# HC32K118 register map
File version: 1.0
CPU: CM0+ r0p1, little endian, no MPU, no FPU, 2 interrupt priority bits
Registers are 32-bit, read-write, reset 0x0 unless marked. A register's access mark holds for its fields unless they carry their own. Offsets are from the block's base; [hi:lo] are bit positions; {n}, {i} and the like mark numbered series.

## PERIC
Base 0x40013400
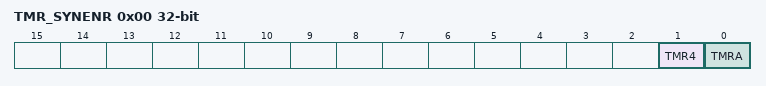
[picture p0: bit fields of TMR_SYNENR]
0x00 TMR_SYNENR
  [1] TMR4, [0] TMRA

## PWC
Base 0x40014000
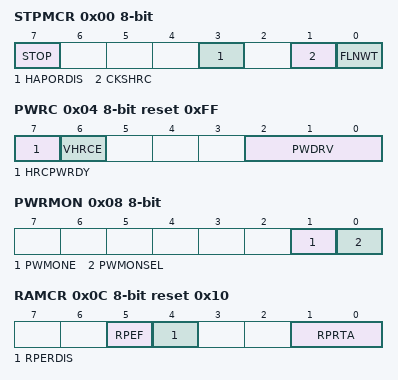
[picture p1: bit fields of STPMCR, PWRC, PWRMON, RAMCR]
0x00 STPMCR 8-bit
  [7] STOP, [3] HAPORDIS, [1] CKSHRC, [0] FLNWT
0x04 PWRC 8-bit reset 0xFF
  [7] HRCPWRDY, [6] VHRCE, [2:0] PWDRV
0x08 PWRMON 8-bit
  [1] PWMONE, [0] PWMONSEL
0x0C RAMCR 8-bit reset 0x10
  [5] RPEF, [4] RPERDIS, [1:0] RPRTA
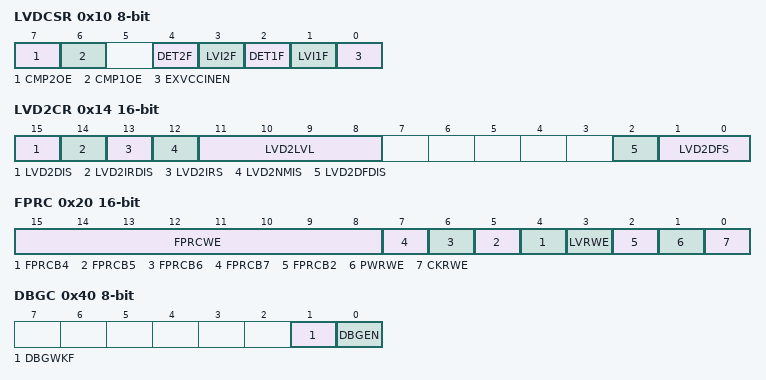
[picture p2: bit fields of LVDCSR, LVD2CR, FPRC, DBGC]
0x10 LVDCSR 8-bit
  [7] CMP2OE, [6] CMP1OE, [4] DET2F, [3] LVI2F, [2] DET1F, [1] LVI1F, [0] EXVCCINEN
0x14 LVD2CR 16-bit
  [15] LVD2DIS, [14] LVD2IRDIS, [13] LVD2IRS, [12] LVD2NMIS, [11:8] LVD2LVL, [2] LVD2DFDIS, [1:0] LVD2DFS
0x20 FPRC 16-bit
  [15:8] FPRCWE wo, [n] FPRCB{n} (n=4..7), [3] LVRWE, [2] FPRCB2, [1] PWRWE, [0] CKRWE
0x40 DBGC 8-bit
  [1] DBGWKF ro, [0] DBGEN

## RMU
Base 0x40014100
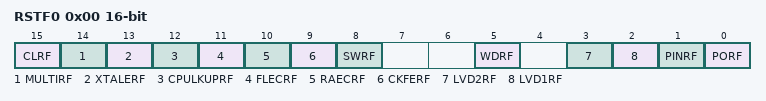
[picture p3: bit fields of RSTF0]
0x00 RSTF0 16-bit
  [15] CLRF, [14] MULTIRF, [13] XTALERF, [12] CPULKUPRF, [11] FLECRF, [10] RAECRF, [9] CKFERF, [8] SWRF, [5] WDRF, [3] LVD2RF, [2] LVD1RF, [1] PINRF, [0] PORF

## RTC
Base 0x4000D400
0x00 CR0 8-bit
  [0] RESET
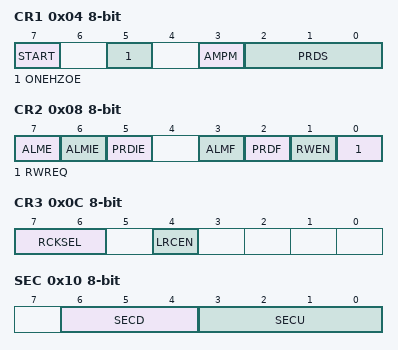
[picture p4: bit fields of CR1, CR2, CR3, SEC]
0x04 CR1 8-bit
  [7] START, [5] ONEHZOE, [3] AMPM, [2:0] PRDS
0x08 CR2 8-bit
  [7] ALME, [6] ALMIE, [5] PRDIE, [3] ALMF, [2] PRDF, [1] RWEN, [0] RWREQ
0x0C CR3 8-bit
  [7:6] RCKSEL, [4] LRCEN
0x10 SEC 8-bit
  [6:4] SECD, [3:0] SECU
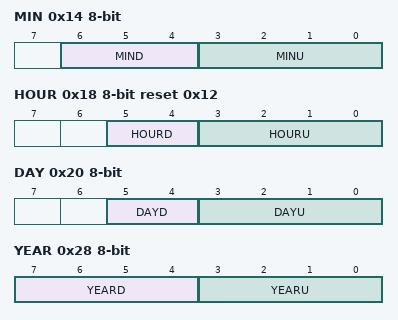
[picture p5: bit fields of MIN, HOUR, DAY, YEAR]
0x14 MIN 8-bit
  [6:4] MIND, [3:0] MINU
0x18 HOUR 8-bit reset 0x12
  [5:4] HOURD, [3:0] HOURU
0x1C WEEK 8-bit
  [2:0] WEEK
0x20 DAY 8-bit
  [5:4] DAYD, [3:0] DAYU
0x24 MON 8-bit
  [4:0] MON
0x28 YEAR 8-bit
  [7:4] YEARD, [3:0] YEARU
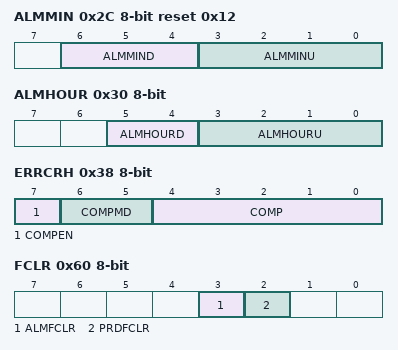
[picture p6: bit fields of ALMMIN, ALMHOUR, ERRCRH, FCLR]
0x2C ALMMIN 8-bit reset 0x12
  [6:4] ALMMIND, [3:0] ALMMINU
0x30 ALMHOUR 8-bit
  [5:4] ALMHOURD, [3:0] ALMHOURU
0x34 ALMWEEK 8-bit
  [6:0] ALMWEEK
0x38 ERRCRH 8-bit
  [7] COMPEN, [6:5] COMPMD, [4:0] COMP
0x3C ERRCRL 8-bit reset 0x20
0x60 FCLR 8-bit
  [3] ALMFCLR, [2] PRDFCLR

## SPI1 — desc SPI
Base 0x40003800
Same registers: SPI2 0x40003C00
0x00 DR
  [15:0] SPD
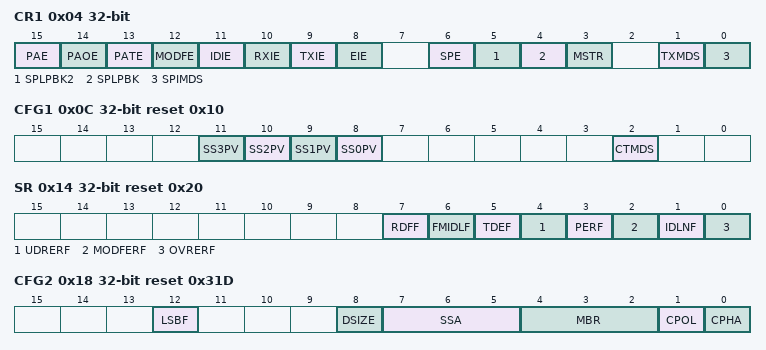
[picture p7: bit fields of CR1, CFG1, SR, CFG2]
0x04 CR1
  [15] PAE, [14] PAOE, [13] PATE, [12] MODFE, [11] IDIE, [10] RXIE, [9] TXIE, [8] EIE, [6] SPE, [5] SPLPBK2, [4] SPLPBK, [3] MSTR, [1] TXMDS, [0] SPIMDS
0x0C CFG1 reset 0x10
  [n+8] SS{n}PV (n=0..3), [2] CTMDS
0x14 SR reset 0x20
  [7] RDFF, [6] FMIDLF, [5] TDEF ro, [4] UDRERF, [3] PERF, [2] MODFERF, [1] IDLNF ro, [0] OVRERF
0x18 CFG2 reset 0x31D
  [12] LSBF, [8] DSIZE, [7:5] SSA, [4:2] MBR, [1] CPOL, [0] CPHA

## SRAMC
Base 0x40010C00
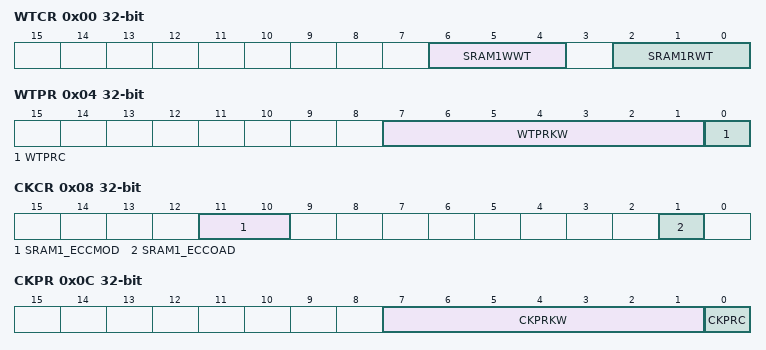
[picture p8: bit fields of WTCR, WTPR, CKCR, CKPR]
0x00 WTCR
  [6:4] SRAM1WWT, [2:0] SRAM1RWT
0x04 WTPR
  [7:1] WTPRKW, [0] WTPRC
0x08 CKCR
  [11:10] SRAM1_ECCMOD, [1] SRAM1_ECCOAD
0x0C CKPR
  [7:1] CKPRKW, [0] CKPRC
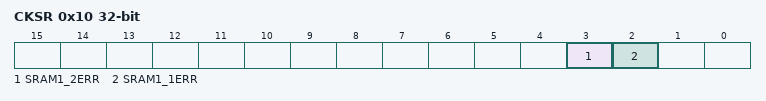
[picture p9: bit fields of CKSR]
0x10 CKSR
  [3] SRAM1_2ERR, [2] SRAM1_1ERR
0x14 SRAM1_EIEN
  [0] EIEN
0x18 SRAM1_EIBIT0
0x1C SRAM1_EIBIT1
  [6:0] EIBIT
0x20 SRAM1_ECCERRADDR
  [16:0] ECCERRADDR

## SWDT
Base 0x4000CC00
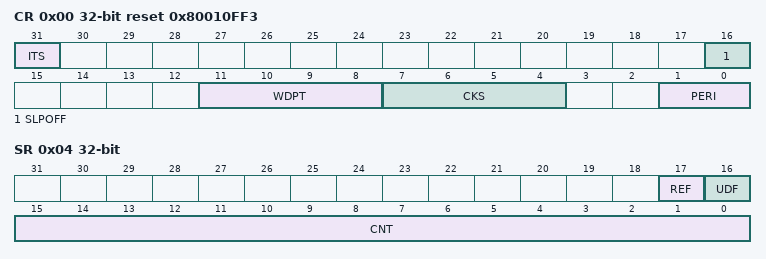
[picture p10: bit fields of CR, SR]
0x00 CR reset 0x80010FF3
  [31] ITS, [16] SLPOFF, [11:8] WDPT, [7:4] CKS, [1:0] PERI
0x04 SR
  [17] REF, [16] UDF, [15:0] CNT ro
0x08 RR
  [15:0] RF

## TMR0
Base 0x40005800
0x00 CNTAR
  [15:0] CNTA
0x08 CMPAR reset 0xFFFF
  [15:0] CMPA
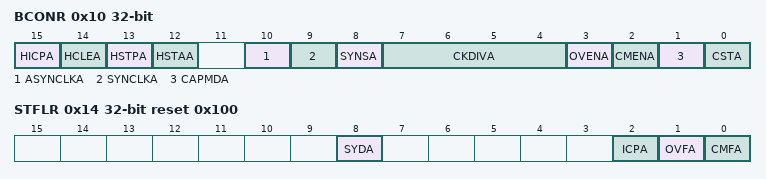
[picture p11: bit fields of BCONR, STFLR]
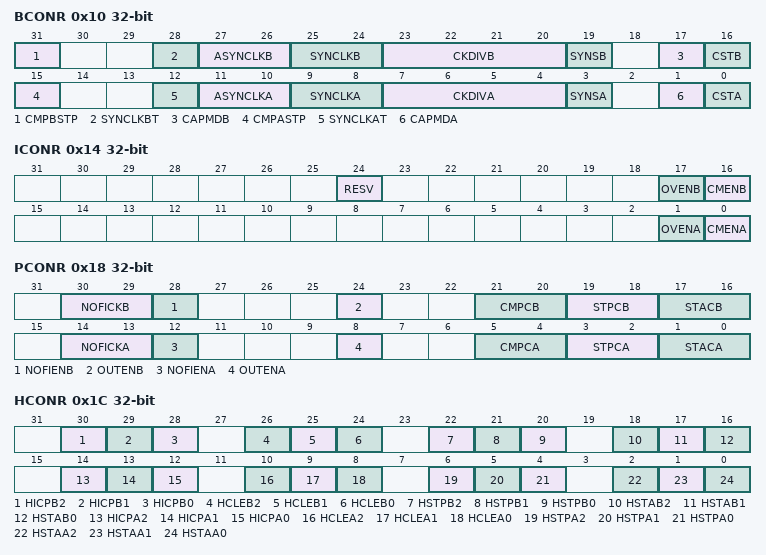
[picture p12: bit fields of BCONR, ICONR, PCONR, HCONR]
0x10 BCONR
  [15] HICPA, [14] HCLEA, [13] HSTPA, [12] HSTAA, [10] ASYNCLKA, [9] SYNCLKA, [8] SYNSA, [7:4] CKDIVA, [3] OVENA, [2] CMENA, [1] CAPMDA, [0] CSTA
0x14 STFLR reset 0x100
  [8] SYDA, [2] ICPA, [1] OVFA, [0] CMFA

## TMR21 — desc TMR2
Base 0x40005C00
Same registers: TMR22 0x40006000
0x00 CNTAR
  [15:0] CNTA
0x04 CNTBR
  [15:0] CNTB
0x08 CMPAR reset 0xFFFF
  [15:0] CMPA
0x0C CMPBR reset 0xFFFF
  [15:0] CMPB
0x10 BCONR
  [31] CMPBSTP, [28] SYNCLKBT, [27:26] ASYNCLKB, [25:24] SYNCLKB, [23:20] CKDIVB, [19] SYNSB, [17] CAPMDB, [16] CSTB, [15] CMPASTP, [12] SYNCLKAT, [11:10] ASYNCLKA, [9:8] SYNCLKA, [7:4] CKDIVA, [3] SYNSA, [1] CAPMDA, [0] CSTA
0x14 ICONR
  [24] RESV, [17] OVENB, [16] CMENB, [1] OVENA, [0] CMENA
0x18 PCONR
  [30:29] NOFICKB, [28] NOFIENB, [24] OUTENB, [21:20] CMPCB, [19:18] STPCB, [17:16] STACB, [14:13] NOFICKA, [12] NOFIENA, [8] OUTENA, [5:4] CMPCA, [3:2] STPCA, [1:0] STACA
0x1C HCONR
  [30] HICPB2, [29] HICPB1, [28] HICPB0, [26] HCLEB2, [25] HCLEB1, [24] HCLEB0, [22] HSTPB2, [21] HSTPB1, [20] HSTPB0, [18] HSTAB2, [17] HSTAB1, [16] HSTAB0, [14] HICPA2, [13] HICPA1, [12] HICPA0, [10] HCLEA2, [9] HCLEA1, [8] HCLEA0, [6] HSTPA2, [5] HSTPA1, [4] HSTPA0, [2] HSTAA2, [1] HSTAA1, [0] HSTAA0
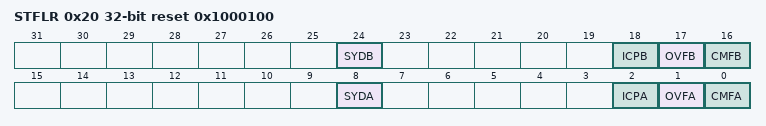
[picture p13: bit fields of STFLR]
0x20 STFLR reset 0x1000100
  [24] SYDB, [18] ICPB, [17] OVFB, [16] CMFB, [8] SYDA, [2] ICPA, [1] OVFA, [0] CMFA
